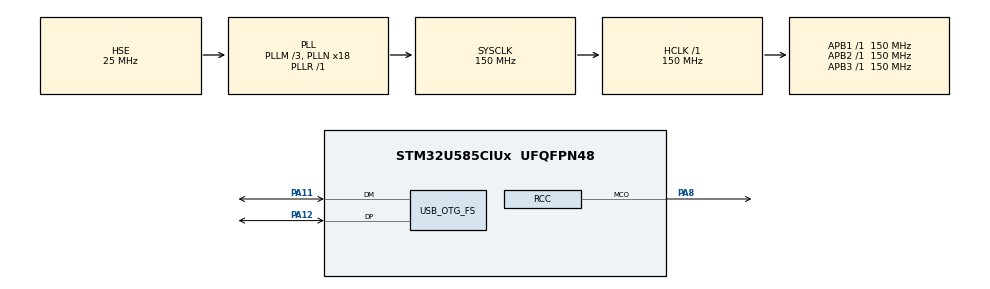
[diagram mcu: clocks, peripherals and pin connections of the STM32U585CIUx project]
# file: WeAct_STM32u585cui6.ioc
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CORTEX_M33_NS.userName=CORTEX_M33
Mcu.Family=STM32U5
Mcu.Name=STM32U585CIUx
Mcu.Package=UFQFPN48
NVIC.OTG_FS_IRQn=true\:0\:0\:false\:false\:true\:true\:true\:true
NVIC.PriorityGroup=NVIC_PRIORITYGROUP_4
PA11.Mode=Device_Only
PA11.Signal=USB_OTG_FS_DM
PA12.Mode=Device_Only
PA12.Signal=USB_OTG_FS_DP
PA13\ (JTMS/SWDIO).Mode=Serial_Wire
PA13\ (JTMS/SWDIO).Signal=DEBUG_JTMS-SWDIO
PA14\ (JTCK/SWCLK).Mode=Serial_Wire
PA14\ (JTCK/SWCLK).Signal=DEBUG_JTCK-SWCLK
PA8.Mode=Clock-out
PA8.Signal=RCC_MCO
PH0-OSC_IN\ (PH0).Mode=HSE-External-Oscillator
PH0-OSC_IN\ (PH0).Signal=RCC_OSC_IN
PH1-OSC_OUT\ (PH1).Mode=HSE-External-Oscillator
PH1-OSC_OUT\ (PH1).Signal=RCC_OSC_OUT
ProjectManager.HeapSize=0x200
ProjectManager.StackSize=0x400
ProjectManager.TargetToolchain=STM32CubeIDE
RCC.ADCFreq_Value=16000000
RCC.AHBFreq_Value=150000000
RCC.APB1Freq_Value=150000000
RCC.APB1TimFreq_Value=150000000
RCC.APB2Freq_Value=150000000
RCC.APB2TimFreq_Value=150000000
RCC.APB3Freq_Value=150000000
RCC.CortexFreq_Value=150000000
RCC.EPOD_VALUE=25000000
RCC.HCLKFreq_Value=150000000
RCC.HSE_VALUE=25000000
RCC.HSI48_VALUE=48000000
RCC.HSI_VALUE=16000000
RCC.LSE_VALUE=32768
RCC.LSIDIV_VALUE=32000
RCC.MSIClockRange=RCC_MSIRANGE_0
RCC.MSI_VALUE=48000000
RCC.PLL1R=1
RCC.PLL2FRACN=0
RCC.PLL3FRACN=0
RCC.PLLFRACN=0
RCC.PLLM=3
RCC.PLLN=18
RCC.PLLSourceVirtual=RCC_PLLSOURCE_HSE
RCC.RCC_MCO1SourceVirtual=RCC_MCO1SOURCE_HSE
RCC.SYSCLKFreq_VALUE=150000000
RCC.SYSCLKSource=RCC_SYSCLKSOURCE_PLLCLK
RCC.USBFreq_Value=48000000
RCC.VCOOutputFreq_Value=150000000
USBX.BSP.number=1
USBX.Core_System=1
USBX.USBD_CDCACM_EPIN_ADDR=2
USBX.USBD_CDCACM_EPOUT_ADDR=3
USBX.USBX_DEVICE_SYS_SIZE=10*1024
USBX.UX_DEVICE_APP_MEM_POOL_SIZE_STANDALONE=10*1024
USBX.UX_DEVICE_CDC_ACM=1
USBX.UX_Device_Controller=1
USBX.UX_Device_CoreStack=1
USBX0.BSP.STBoard=false
USBX0.BSP.api=Unknown
USBX0.BSP.condition=SEMAOoUSBOoOTGOoFSOoDEVICEOoFOROoUSBX & \!DIE455
USBX0.BSP.instance=USB_OTG_FS
USBX0.BSP.ip=USB_OTG_FS
USBX0.BSP.mode=Device_Only
USBX0.BSP.name=USBDevice
USBX0.BSP.solution=USB_OTG_FS
USB_OTG_FS.VirtualMode=Device_Only
VP_ICACHE_VS_ENABLE_ICACHE_MEMORY.Mode=Memoryregions
VP_LPBAMQUEUE_VS_QUEUE.Mode=QUEUEMODE
VP_LPBAM_VS_SIG1.Mode=SmartRun
VP_LPBAM_VS_SIG4.Mode=LPDMA1
VP_MEMORYMAP_VS_MEMORYMAP.Mode=CurAppReg
VP_PWR_VS_SECSignals.Mode=Security/Privilege
VP_USBX_Core_System.Mode=Core_System
VP_USBX_UX\ Device\ CDC\ ACM\ Class_FS.Mode=UX_Device_class_CDC_ACM_FS
VP_USBX_UX\ Device\ Controller_FS.Mode=UX_Device_Controller_FS
VP_USBX_UX\ Device\ CoreStack_FS.Mode=UX_Device_CoreStack_FS
board=custom

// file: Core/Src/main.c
/* USER CODE BEGIN Header */
/**
  ******************************************************************************
  * @file           : main.c
  * @brief          : Main program body
  ******************************************************************************
  * @attention
  *
  * Copyright (c) 2025 STMicroelectronics.
  * All rights reserved.
  *
  * This software is licensed under terms that can be found in the LICENSE file
  * in the root directory of this software component.
  * If no LICENSE file comes with this software, it is provided AS-IS.
  *
  ******************************************************************************
  */
/* USER CODE END Header */
#include "main.h"
#include "app_usbx_device.h"

PCD_HandleTypeDef hpcd_USB_OTG_FS;

void SystemClock_Config(void);
static void MX_GPIO_Init(void);
static void MX_ICACHE_Init(void);

int main(void)
{

  /* MCU Configuration--------------------------------------------------------*/

  /* Reset of all peripherals, Initializes the Flash interface and the Systick. */
  HAL_Init();

  /* Configure the system clock */
  SystemClock_Config();

  /* Initialize all configured peripherals */
  MX_GPIO_Init();
  MX_ICACHE_Init();
  MX_USB_OTG_FS_PCD_Init();
  MX_USBX_Device_Init();
  /* USER CODE BEGIN 2 */
  /* USER CODE BEGIN 2 */
  /* initialize the device controller driver*/
  ux_dcd_stm32_initialize((ULONG)USB_OTG_FS, (ULONG)&hpcd_USB_OTG_FS);

  /* Start device USB */
  HAL_PCD_Start(&hpcd_USB_OTG_FS);
  /* USER CODE END 2 */

  /* Infinite loop */
  /* USER CODE BEGIN WHILE */
  while (1)
  {
		ux_device_stack_tasks_run();
    /* USER CODE END WHILE */

  }
}

void SystemClock_Config(void)
{
  RCC_OscInitTypeDef RCC_OscInitStruct = {0};
  RCC_ClkInitTypeDef RCC_ClkInitStruct = {0};

  /** Configure the main internal regulator output voltage
  */
  if (HAL_PWREx_ControlVoltageScaling(PWR_REGULATOR_VOLTAGE_SCALE1) != HAL_OK)
  {
    Error_Handler();
  }

  /** Initializes the CPU, AHB and APB buses clocks
  */
  RCC_OscInitStruct.OscillatorType = RCC_OSCILLATORTYPE_HSI48|RCC_OSCILLATORTYPE_HSE;
  RCC_OscInitStruct.HSEState = RCC_HSE_ON;
  RCC_OscInitStruct.HSI48State = RCC_HSI48_ON;
  RCC_OscInitStruct.PLL.PLLState = RCC_PLL_ON;
  RCC_OscInitStruct.PLL.PLLSource = RCC_PLLSOURCE_HSE;
  RCC_OscInitStruct.PLL.PLLMBOOST = RCC_PLLMBOOST_DIV2;
  RCC_OscInitStruct.PLL.PLLM = 3;
  RCC_OscInitStruct.PLL.PLLN = 18;
  RCC_OscInitStruct.PLL.PLLP = 2;
  RCC_OscInitStruct.PLL.PLLQ = 2;
  RCC_OscInitStruct.PLL.PLLR = 1;
  RCC_OscInitStruct.PLL.PLLRGE = RCC_PLLVCIRANGE_1;
  RCC_OscInitStruct.PLL.PLLFRACN = 0;
  if (HAL_RCC_OscConfig(&RCC_OscInitStruct) != HAL_OK)
  {
    Error_Handler();
  }

  /** Initializes the CPU, AHB and APB buses clocks
  */
  RCC_ClkInitStruct.ClockType = RCC_CLOCKTYPE_HCLK|RCC_CLOCKTYPE_SYSCLK
                              |RCC_CLOCKTYPE_PCLK1|RCC_CLOCKTYPE_PCLK2
                              |RCC_CLOCKTYPE_PCLK3;
  RCC_ClkInitStruct.SYSCLKSource = RCC_SYSCLKSOURCE_PLLCLK;
  RCC_ClkInitStruct.AHBCLKDivider = RCC_SYSCLK_DIV1;
  RCC_ClkInitStruct.APB1CLKDivider = RCC_HCLK_DIV1;
  RCC_ClkInitStruct.APB2CLKDivider = RCC_HCLK_DIV1;
  RCC_ClkInitStruct.APB3CLKDivider = RCC_HCLK_DIV1;

  if (HAL_RCC_ClockConfig(&RCC_ClkInitStruct, FLASH_LATENCY_4) != HAL_OK)
  {
    Error_Handler();
  }

  /** MCO configuration
  */
  HAL_RCC_MCOConfig(RCC_MCO1, RCC_MCO1SOURCE_HSE, RCC_MCODIV_1);
}

static void MX_ICACHE_Init(void)
{

}

void MX_USB_OTG_FS_PCD_Init(void)
{

  hpcd_USB_OTG_FS.Instance = USB_OTG_FS;
  hpcd_USB_OTG_FS.Init.dev_endpoints = 6;
  hpcd_USB_OTG_FS.Init.speed = PCD_SPEED_FULL;
  hpcd_USB_OTG_FS.Init.phy_itface = PCD_PHY_EMBEDDED;
  hpcd_USB_OTG_FS.Init.Sof_enable = DISABLE;
  hpcd_USB_OTG_FS.Init.low_power_enable = DISABLE;
  hpcd_USB_OTG_FS.Init.lpm_enable = DISABLE;
  hpcd_USB_OTG_FS.Init.battery_charging_enable = DISABLE;
  hpcd_USB_OTG_FS.Init.use_dedicated_ep1 = DISABLE;
  hpcd_USB_OTG_FS.Init.vbus_sensing_enable = DISABLE;
  hpcd_USB_OTG_FS.Init.dma_enable = DISABLE;
  if (HAL_PCD_Init(&hpcd_USB_OTG_FS) != HAL_OK)
  {
    Error_Handler();
  }

}

static void MX_GPIO_Init(void)
{
  GPIO_InitTypeDef GPIO_InitStruct = {0};

  /* GPIO Ports Clock Enable */
  __HAL_RCC_GPIOH_CLK_ENABLE();
  __HAL_RCC_GPIOA_CLK_ENABLE();

  /*Configure GPIO pin : PA8 */
  GPIO_InitStruct.Pin = GPIO_PIN_8;
  GPIO_InitStruct.Mode = GPIO_MODE_AF_PP;
  GPIO_InitStruct.Pull = GPIO_NOPULL;
  GPIO_InitStruct.Speed = GPIO_SPEED_FREQ_HIGH;
  GPIO_InitStruct.Alternate = GPIO_AF0_MCO;
  HAL_GPIO_Init(GPIOA, &GPIO_InitStruct);

}

void Error_Handler(void)
{
  __disable_irq();
  while (1)
  {
  }
}
